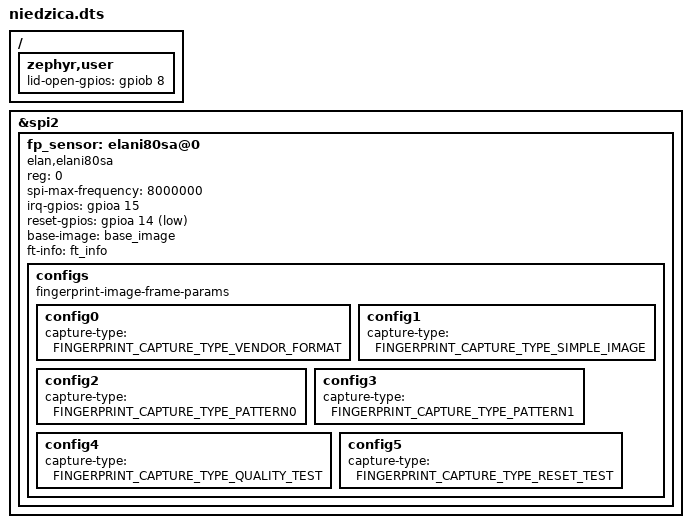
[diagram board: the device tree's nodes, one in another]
/* Copyright 2026 The ChromiumOS Authors.
 * Use of this source code is governed by a BSD-style license that can be
 * found in the LICENSE file.
 */

#include "common.dtsi"
#include "fp_led.dtsi"

/ {
	zephyr,user {
		lid-open-gpios = <&gpiob 8 (GPIO_PULL_UP | GPIO_ACTIVE_HIGH)>;
	};
};

#define ELANI80SA_COMMON_IMAGE_PROPS \
	width = <80>; \
	height = <80>; \
	frame-size = <12800>; \
	v4l2-pixel-format = "V4L2_PIX_FMT_GREY";

#define ELANI80SA_RAW_IMAGE_PROPS \
	ELANI80SA_COMMON_IMAGE_PROPS \
	bits-per-pixel = <8>; \
	image-data-offset-bytes = <6400>;

#define ELANI80SA_REAL_IMAGE_PROPS \
	ELANI80SA_COMMON_IMAGE_PROPS \
	bits-per-pixel = <16>; \
	image-data-offset-bytes = <0>;

&spi2 {
	fp_sensor: elani80sa@0 {
		compatible = "elan,elani80sa";
		reg = <0>;
		spi-max-frequency = <8000000>;

		configs {
			compatible = "fingerprint-image-frame-params";
			config0 {
				ELANI80SA_RAW_IMAGE_PROPS
				capture-type = "FINGERPRINT_CAPTURE_TYPE_VENDOR_FORMAT";
			};
			config1 {
				ELANI80SA_REAL_IMAGE_PROPS
				capture-type = "FINGERPRINT_CAPTURE_TYPE_SIMPLE_IMAGE";
			};
			config2 {
				ELANI80SA_REAL_IMAGE_PROPS
				capture-type = "FINGERPRINT_CAPTURE_TYPE_PATTERN0";
			};
			config3 {
				ELANI80SA_REAL_IMAGE_PROPS
				capture-type = "FINGERPRINT_CAPTURE_TYPE_PATTERN1";
			};
			config4 {
				ELANI80SA_RAW_IMAGE_PROPS
				capture-type = "FINGERPRINT_CAPTURE_TYPE_QUALITY_TEST";
			};
			config5 {
				ELANI80SA_REAL_IMAGE_PROPS
				capture-type = "FINGERPRINT_CAPTURE_TYPE_RESET_TEST";
			};
		};

		irq-gpios = <&gpioa 15 GPIO_ACTIVE_HIGH>;
		reset-gpios = <&gpioa 14 GPIO_ACTIVE_LOW>;
		base-image = <&base_image>;
		ft-info = <&ft_info>;
	};
};
